# Cortex_M52 register map
Vendor: Arm Ltd.; Series: ARMv8.1-M Mainline; File version: 1.0.0
CPU: other r0p0, little endian, MPU, FPU, double-precision FPU, DSP, 8 interrupt priority bits
Registers are 32-bit, read-write, reset 0x0 unless marked. A register's access mark holds for its fields unless they carry their own. Offsets are from the block's base; [hi:lo] are bit positions; lines under a group give offsets from that group; {n}, {i} and the like mark numbered series.

## ITM — Instrumentation Trace Macrocell: 32 stimulus ports that software writes to emit printf-style trace over SWO/TPIU, plus timestamps and the DWT event/PC-sample packets. Needs DEMCR.TRCENA = 1, an unlocked LAR on ARMv7-M, TCR.ITMENA and the port enabled in TER.
Base 0xE0000000
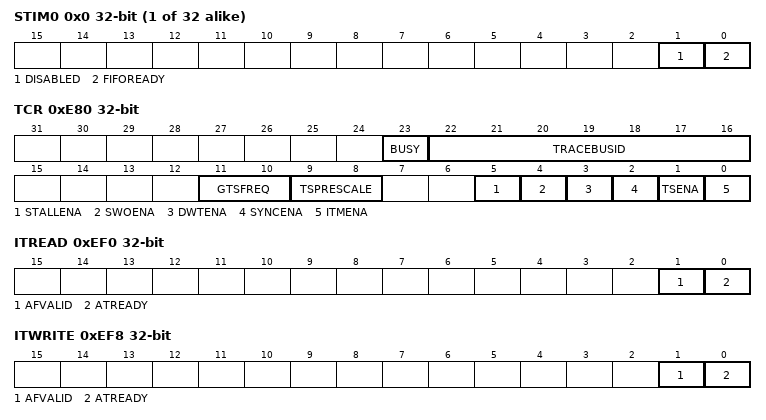
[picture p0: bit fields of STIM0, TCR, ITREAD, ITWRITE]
{0x0+4i} STIM{i} (i=0..31) wo — Stimulus Port n: a write emits an 8/16/32-bit software trace packet on port n (if enabled in TER). Reads return FIFOREADY, so software can wait for space.
  [1] DISABLED — Read: 1 = the port is disabled (TER bit clear, ITM disabled, or privilege violation) and writes are discarded.
  [0] FIFOREADY — Read: 1 = the stimulus port can accept a write (FIFO not full), 0 = wait.
0xE00 TER — Trace Enable Register: bit k enables stimulus port k. Privileged access only.
  [31:0] STIMENA — Bit k: stimulus port 32n+k enabled.
0xE40 TPR — Trace Privilege Register: which stimulus ports unprivileged code may write.
  [3:0] PRIVMASK — Bit k = 1: stimulus port group k is privileged-only (unprivileged writes are ignored). ARMv7-M: 4 groups of 8 ports; ARMv8-M: one bit per port.
0xE80 TCR — Trace Control Register: ITM enable, timestamps, synchronization, DWT packet forwarding and the ATB source ID.
  [23] BUSY ro — Read-only: 1 = the ITM is still processing events. Wait for 0 before disabling or changing the configuration.
  [22:16] TRACEBUSID — ATB source ID of the ITM (must be unique and non-zero; 1 is conventional). The TPIU formatter tags packets with it when several sources share the port.
  [11:10] GTSFREQ — Global timestamp frequency: 0 = disabled, 1 = every 128 cycles, 2 = every 8192 cycles, 3 = after every packet when the trace bus is idle.
  [9:8] TSPRESCALE — Local timestamp prescaler: 0 = none, 1 = divide by 4, 2 = by 16, 3 = by 64.
    0=None (No prescaling); 1=Div4 (Divide by 4); 2=Div16 (Divide by 16); 3=Div64 (Divide by 64)
  [5] STALLENA — Stall enable (ARMv8-M): 1 = a stimulus-port write to a full FIFO stalls the processor instead of being dropped, guaranteeing complete trace.
  [4] SWOENA — Timestamp clock: 1 = the local timestamp counter runs from the (asynchronous) SWO clock, 0 = from the processor clock. Set with TSENA in SWO mode.
  [3] DWTENA — Enable forwarding of DWT hardware event packets (PC samples, watchpoints, exception trace, counters) through the ITM (TXENA on ARMv8-M).
  [2] SYNCENA — Synchronization packets enable (rate from DWT.CTRL.SYNCTAP). Needed for the receiver to recover framing.
  [1] TSENA — Local timestamp packets enable: a delta timestamp follows each group of packets.
  [0] ITMENA — ITM enable. Clear before reconfiguring; wait for BUSY = 0 before disabling.
0xEF0 ITREAD ro — Integration Test Read Register (integration mode only).
  [1] AFVALID — Integration: the AFVALID (flush request) input.
  [0] ATREADY — Integration: the ATREADY input from the ATB.
0xEF8 ITWRITE wo — Integration Test Write Register (integration mode only).
  [1] AFVALID — Integration: drives the ITM AFREADY output.
  [0] ATREADY — Integration: drives the ITM ATVALID output (the header reuses the ITREAD names).
0xF00 ITCTRL — Integration Mode Control Register: 1 = the ITM ATB outputs are driven from ITWRITE for topology testing.
  [0] IME — Integration mode enable: 1 = the IT* registers control the ATB signals for topology detection; 0 = normal operation.
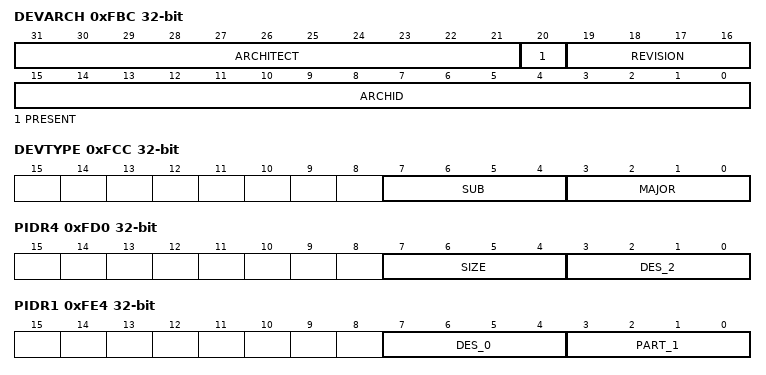
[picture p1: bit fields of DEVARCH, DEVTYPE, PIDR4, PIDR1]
0xFBC DEVARCH ro — Device Architecture Register: CoreSight ARCHID of the ITM (0x1A01).
  [31:21] ARCHITECT — JEP106 code of the architect (Arm: 0x23B).
  [20] PRESENT — 1 = DEVARCH is present and its contents are valid.
  [19:16] REVISION — Architecture revision.
  [15:0] ARCHID — Architecture ID, including the architecture part number [11:0] and revision [15:12].
0xFCC DEVTYPE ro — Device Type Register: 0x43 (trace source, processor).
  [7:4] SUB — Sub type within the major class.
  [3:0] MAJOR — Major type: 0 miscellaneous, 1 trace sink, 2 trace link, 3 trace source, 4 debug control, 5 debug logic, 6 PMU.
0xFD0 PIDR4 ro — Peripheral Identification Register 4: JEP106 continuation code and component size.
  [7:4] SIZE — Log2 of the number of 4 KB blocks the component occupies (0 = one block).
  [3:0] DES_2 — JEP106 continuation code of the designer (Arm: 0x4).
{0xFC0+4i} PIDR{i} ro (i=5..7) — Peripheral Identification Register {i} (reserved, reads as zero).
0xFE0 PIDR0 ro — Peripheral Identification Register 0: part number bits [7:0].
  [7:0] PART_0 — Part number bits [7:0].
0xFE4 PIDR1 ro — Peripheral Identification Register 1: part number bits [11:8] and designer bits [3:0].
  [7:4] DES_0 — JEP106 identity code bits [3:0] of the designer.
  [3:0] PART_1 — Part number bits [11:8].
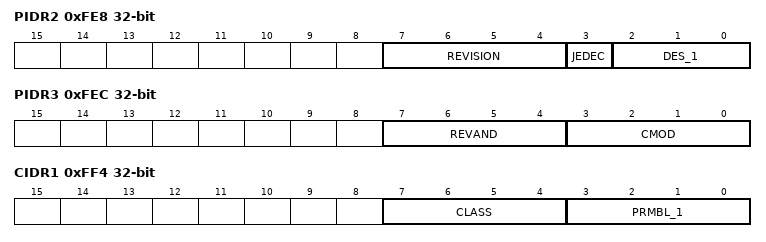
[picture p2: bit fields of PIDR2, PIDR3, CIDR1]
0xFE8 PIDR2 ro — Peripheral Identification Register 2: designer bits [6:4], JEDEC flag and revision.
  [7:4] REVISION — Component major revision.
  [3] JEDEC — Always 1: the designer ID is a JEDEC JEP106 code.
  [2:0] DES_1 — JEP106 identity code bits [6:4] of the designer.
0xFEC PIDR3 ro — Peripheral Identification Register 3: customer modified and minor revision.
  [7:4] REVAND — Minor revision (metal fix) number.
  [3:0] CMOD — Customer Modified: 0 if the component has not been modified by the integrator.
0xFF0 CIDR0 ro — Component Identification Register 0: preamble byte 0 (0x0D).
  [7:0] PRMBL_0 — Preamble, reads as 0x0D.
0xFF4 CIDR1 ro — Component Identification Register 1: component class and preamble.
  [7:4] CLASS — Component class: 0x1 ROM table, 0x9 CoreSight component, 0xE generic IP, 0xF CoreLink/PrimeCell.
  [3:0] PRMBL_1 — Preamble, reads as 0x0.
0xFF8 CIDR2 ro — Component Identification Register 2: preamble byte 2 (0x05).
  [7:0] PRMBL_2 — Preamble, reads as 0x05.
0xFFC CIDR3 ro — Component Identification Register 3: preamble byte 3 (0xB1).
  [7:0] PRMBL_3 — Preamble, reads as 0xB1.
